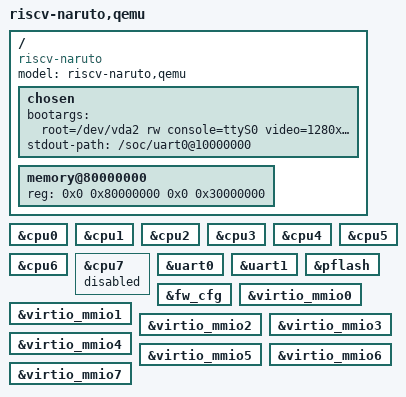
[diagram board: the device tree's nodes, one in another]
#include "naruto.dtsi"

/ {
	#address-cells = <0x2>;
	#size-cells = <0x2>;
	compatible = "riscv-naruto";
	model = "riscv-naruto,qemu";

	chosen {
		bootargs = "root=/dev/vda2 rw console=ttyS0 video=1280x720";
		stdout-path = "/soc/uart0@10000000";
	};

	memory@80000000 {
		device_type = "memory";
		reg = <0x0 0x80000000 0x0 0x30000000>;
	};
};

&cpu0 {
	status = "okay";
};

&cpu1 {
	status = "okay";
};

&cpu2 {
	status = "okay";
};

&cpu3 {
	status = "okay";
};

&cpu4 {
	status = "okay";
};

&cpu5 {
	status = "okay";
};

&cpu6 {
	status = "okay";
};

&cpu7 {
	status = "disabled";
};

&uart0 {
	status = "okay";
};

&uart1 {
	status = "okay";
};

&pflash {
	status = "okay";
};

&fw_cfg {
	status = "okay";
};

&virtio_mmio0 {
	status = "okay";
};

&virtio_mmio1 {
	status = "okay";
};

&virtio_mmio2 {
	status = "okay";
};

&virtio_mmio3 {
	status = "okay";
};

&virtio_mmio4 {
	status = "okay";
};

&virtio_mmio5 {
	status = "okay";
};

&virtio_mmio6 {
	status = "okay";
};

&virtio_mmio7 {
	status = "okay";
};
